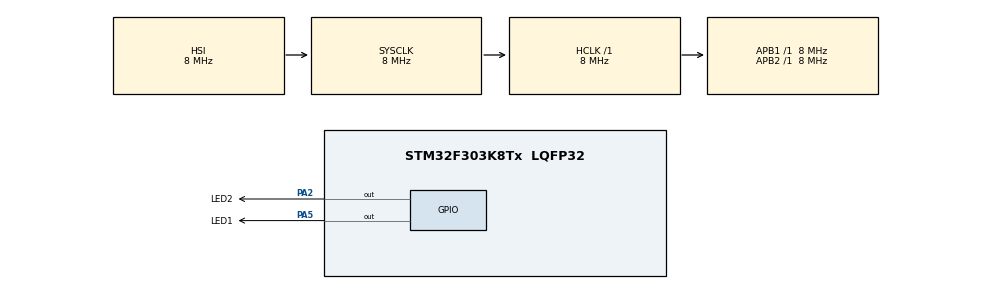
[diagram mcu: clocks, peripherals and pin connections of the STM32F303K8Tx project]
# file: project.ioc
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Mcu.Family=STM32F3
Mcu.Name=STM32F303K8Tx
Mcu.Package=LQFP32
Mcu.PinNb=2
NVIC.EXTI9_5_IRQn=true\:0\:0\:false\:false\:true\:false\:false
PA5.Signal=GPIO_Output
PA5.GPIO_Label=LED1
PA5.GPIO_ModeDefaultEXTI=GPIO_MODE_IT_FALLING
PA5.GPIO_Pull=GPIO_NOPULL
PA5.GPIO_Speed=GPIO_SPEED_FREQ_LOW
PA5.GPIO_ModeDefaultOutputPP=GPIO_MODE_OUTPUT_PP
PA5.GPIO_ModeAF=GPIO_MODE_AF_PP
PA5.GPIO_Remap=0
PA2.Signal=GPIO_Output
PA2.GPIO_Label=LED2
PA2.GPIO_ModeDefaultEXTI=GPIO_MODE_IT_FALLING
PA2.GPIO_Pull=GPIO_NOPULL
PA2.GPIO_Speed=GPIO_SPEED_FREQ_LOW
PA2.GPIO_ModeDefaultOutputPP=GPIO_MODE_OUTPUT_PP
PA2.GPIO_ModeAF=GPIO_MODE_AF_PP
PA2.GPIO_Remap=0
PinoutData.Author=ST
PinoutData.Version=1.0.0
RCC.AHBFreq_Value=8000000
RCC.APB1CLKDivider=RCC_HCLK_DIV1
RCC.APB1Freq_Value=8000000
RCC.APB2CLKDivider=RCC_HCLK_DIV1
RCC.APB2Freq_Value=8000000
RCC.HCLKFreq_Value=8000000
RCC.SYSCLKFreq_VALUE=8000000
RCC.SYSCLKFreq_Value=8000000
RCC.TimAPB1ClockSelection=true
RCC.TimAPB2ClockSelection=true
RCC.HSIState=RCC_HSI_ON
RCC.PLL.PLLState=RCC_PLL_NONE
SYS.SYS_DBGMCU_MCUDBG=0
board=custom

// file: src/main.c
/* USER CODE BEGIN Header */
/**
  ******************************************************************************
  * @file           : main.c
  * @brief          : Main program body
  ******************************************************************************
  * @attention
  *
  * Copyright (c) 2026 STMicroelectronics.
  * All rights reserved.
  *
  * This software is licensed under terms that can be found in the LICENSE file
  * in the root directory of this software component.
  * If no LICENSE file comes with this software, it is provided AS-IS.
  *
  ******************************************************************************
  */
/* USER CODE END Header */
#include "main.h"

/* USER CODE BEGIN Includes */
#include "main.h"
#include "stm32f3xx_hal.h"
/* USER CODE END Includes */

/* USER CODE BEGIN PV */
uint8_t led_state = 0; // 0 for PA2 ON, 1 for PA5 ON
/* USER CODE END PV */

void SystemClock_Config(void);

int main(void)
{

  /* MCU Configuration--------------------------------------------------------*/

  /* Reset of all peripherals, Initializes the Flash interface and the Systick. */
  HAL_Init();

  /* Configure the system clock */
  SystemClock_Config();

  /* Initialize all configured peripherals */
  /* USER CODE BEGIN 2 */
  HAL_GPIO_WritePin(GPIOA, GPIO_PIN_2, GPIO_PIN_RESET);
  HAL_GPIO_WritePin(GPIOA, GPIO_PIN_5, GPIO_PIN_SET());
  HAL_Delay(5000);
  HAL_GPIO_WritePin(GPIOA, GPIO_PIN_2, GPIO_PIN_SET());
  HAL_GPIO_WritePin(GPIOA, GPIO_PIN_5, GPIO_PIN_RESET());
  HAL_Delay(5000);
  /* USER CODE END 2 */

  /* Infinite loop */
  while (1)
  {

  }
}

void SystemClock_Config(void)
{
  RCC_OscInitTypeDef RCC_OscInitStruct = {0};
  RCC_ClkInitTypeDef RCC_ClkInitStruct = {0};

  /** Initializes the RCC Oscillators according to the specified parameters
  * in the RCC_OscInitTypeDef structure.
  */
  RCC_OscInitStruct.OscillatorType = RCC_OSCILLATORTYPE_HSI;
  RCC_OscInitStruct.HSIState = RCC_HSI_ON;
  RCC_OscInitStruct.HSICalibrationValue = RCC_HSICALIBRATION_DEFAULT;
  RCC_OscInitStruct.PLL.PLLState = RCC_PLL_NONE;
  if (HAL_RCC_OscConfig(&RCC_OscInitStruct) != HAL_OK)
  {
    Error_Handler();
  }

  /** Initializes the CPU, AHB and APB buses clocks
  */
  RCC_ClkInitStruct.ClockType = RCC_CLOCKTYPE_HCLK|RCC_CLOCKTYPE_SYSCLK
                              |RCC_CLOCKTYPE_PCLK1|RCC_CLOCKTYPE_PCLK2;
  RCC_ClkInitStruct.SYSCLKSource = RCC_SYSCLKSOURCE_HSI;
  RCC_ClkInitStruct.AHBCLKDivider = RCC_SYSCLK_DIV1;
  RCC_ClkInitStruct.APB1CLKDivider = RCC_HCLK_DIV1;
  RCC_ClkInitStruct.APB2CLKDivider = RCC_HCLK_DIV1;

  if (HAL_RCC_ClockConfig(&RCC_ClkInitStruct, FLASH_LATENCY_0) != HAL_OK)
  {
    Error_Handler();
  }
}

void Error_Handler(void)
{
  __disable_irq();
  while (1)
  {
  }
}
